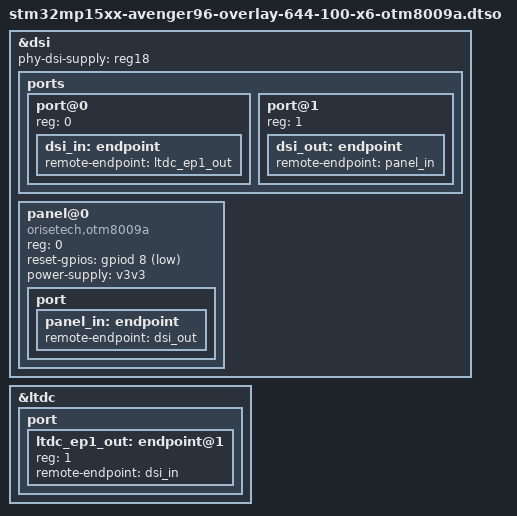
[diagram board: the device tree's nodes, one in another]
// SPDX-License-Identifier: (GPL-2.0+ OR BSD-3-Clause)
/*
 * Copyright (C) 2020 Marek Vasut
 */
#include <dt-bindings/gpio/gpio.h>

/dts-v1/;
/plugin/;

&dsi {
	#address-cells = <1>;
	#size-cells = <0>;

	phy-dsi-supply = <&reg18>;
	status = "okay";

	ports {
		#address-cells = <1>;
		#size-cells = <0>;

		port@0 {
			reg = <0>;
			dsi_in: endpoint {
				remote-endpoint = <&ltdc_ep1_out>;
			};
		};

		port@1 {
			reg = <1>;
			dsi_out: endpoint {
				remote-endpoint = <&panel_in>;
			};
		};
	};

	panel@0 {
		compatible = "orisetech,otm8009a";
		reg = <0>;
		reset-gpios = <&gpiod 8 GPIO_ACTIVE_LOW>;
		power-supply = <&v3v3>;
		status = "okay";

		port {
			panel_in: endpoint {
				remote-endpoint = <&dsi_out>;
			};
		};
	};
};

&ltdc {
	port {
		#address-cells = <1>;
		#size-cells = <0>;

		ltdc_ep1_out: endpoint@1 {
			reg = <1>;
			remote-endpoint = <&dsi_in>;
		};
	};
};
